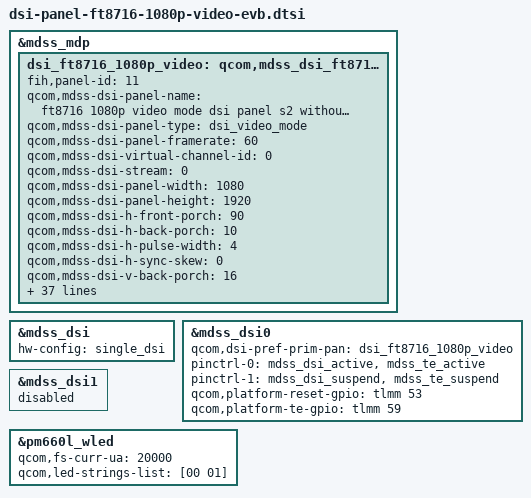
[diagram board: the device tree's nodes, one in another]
/* Copyright (c) 2015, The Linux Foundation. All rights reserved.
 *
 * This program is free software; you can redistribute it and/or modify
 * it under the terms of the GNU General Public License version 2 and
 * only version 2 as published by the Free Software Foundation.
 *
 * This program is distributed in the hope that it will be useful,
 * but WITHOUT ANY WARRANTY; without even the implied warranty of
 * MERCHANTABILITY or FITNESS FOR A PARTICULAR PURPOSE.  See the
 * GNU General Public License for more details.
 */

/*---------------------------------------------------------------------------
 * Templated from dsi-panel-r69006-1080p-video.dtsi
 *---------------------------------------------------------------------------*/
&mdss_mdp {
	dsi_ft8716_1080p_video: qcom,mdss_dsi_ft8716_1080p_video_s2 {
		fih,panel-id = <11>;
		qcom,mdss-dsi-panel-name = "ft8716 1080p video mode dsi panel s2 without DSC";
		qcom,mdss-dsi-panel-type = "dsi_video_mode";
		qcom,mdss-dsi-panel-framerate = <60>;
		qcom,mdss-dsi-virtual-channel-id = <0>;
		qcom,mdss-dsi-stream = <0>;
		qcom,mdss-dsi-panel-width = <1080>;
		qcom,mdss-dsi-panel-height = <1920>;
		qcom,mdss-dsi-h-front-porch = <90>;
		qcom,mdss-dsi-h-back-porch = <10>;
		qcom,mdss-dsi-h-pulse-width = <4>;
		qcom,mdss-dsi-h-sync-skew = <0>;
		qcom,mdss-dsi-v-back-porch = <16>;
		qcom,mdss-dsi-v-front-porch = <16>;
		qcom,mdss-dsi-v-pulse-width = <2>;
		qcom,mdss-dsi-h-left-border = <0>;
		qcom,mdss-dsi-h-right-border = <0>;
		qcom,mdss-dsi-v-top-border = <0>;
		qcom,mdss-dsi-v-bottom-border = <0>;
		qcom,mdss-dsi-bpp = <24>;
		qcom,mdss-dsi-underflow-color = <0xff>;
		qcom,mdss-dsi-border-color = <0>;
		qcom,mdss-dsi-on-command = [29 01 00 00 00 00 02 00 00
			29 01 00 00 00 00 04 ff 87 16 01
			29 01 00 00 00 00 02 00 80
			29 01 00 00 00 00 03 ff 87 16
			29 01 00 00 00 00 02 00 80
			29 01 00 00 00 00 0d d8 80 81 00 01 03 06 09 0b 0c 0b 0a 04
			29 01 00 00 00 00 02 00 90
			29 01 00 00 00 00 0d d8 00 01 01 01 01 00 00 00 01 01 02 05
			29 01 00 00 00 00 02 00 a0
			29 01 00 00 00 00 0d d8 01 02 06 09 0e 15 1b 22 26 26 26 22
			29 01 00 00 00 00 02 00 b0
			29 01 00 00 00 00 0d d8 81 84 86 88 8d 93 98 9d a1 a3 a3 a2
			29 01 00 00 00 00 02 00 c0
			29 01 00 00 00 00 0d d8 82 85 85 85 86 86 87 88 8a 8c 8e 94
			29 01 00 00 00 00 02 00 d0
			29 01 00 00 00 00 0d d8 02 05 07 0a 0d 10 13 17 1c 1d 1f 23
			29 01 00 00 00 00 02 00 e0
			29 01 00 00 00 00 04 d8 fd f0 f3
			29 01 00 00 00 00 02 00 c0
			29 01 00 00 00 00 02 d7 01
			29 01 00 00 00 00 02 00 b4
			29 01 00 00 00 00 02 c0 50
			29 01 00 00 00 00 02 00 00
			29 01 00 00 00 00 04 ff 00 00 00
			05 01 00 00 78 00 02 11 00
			05 01 00 00 0a 00 02 35 00
			05 01 00 00 00 00 02 29 00];
		qcom,mdss-dsi-off-command = [05 01 00 00 14 00 02 28 00
				 05 01 00 00 78 00 02 10 00];
		qcom,mdss-dsi-on-command-state = "dsi_lp_mode";
		qcom,mdss-dsi-off-command-state = "dsi_hs_mode";
		qcom,mdss-dsi-h-sync-pulse = <0>;
		qcom,mdss-dsi-traffic-mode = "non_burst_sync_event";
		qcom,mdss-dsi-bllp-eof-power-mode;
		qcom,mdss-dsi-bllp-power-mode;
		qcom,mdss-dsi-lane-0-state;
		qcom,mdss-dsi-lane-1-state;
		qcom,mdss-dsi-lane-2-state;
		qcom,mdss-dsi-lane-3-state;
		qcom,mdss-dsi-t-clk-post = <0x0d>;
		qcom,mdss-dsi-t-clk-pre = <0x2d>;
		qcom,mdss-dsi-dma-trigger = "trigger_sw";
		qcom,mdss-dsi-mdp-trigger = "none";
		qcom,mdss-dsi-reset-sequence = <1 1>, <0 1>, <1 15>;
	};
};

&dsi_ft8716_1080p_video {
	qcom,mdss-dsi-panel-timings-phy-v2 = [23 1e 07 09 05 03 04 a0
		23 1e 07 09 05 03 04 a0
		23 1e 07 09 05 03 04 a0
		23 1e 07 09 05 03 04 a0
		23 19 07 08 05 03 04 a0];
	qcom,mdss-dsi-bl-pmic-control-type = "bl_ctrl_wled";
	qcom,mdss-dsi-bl-min-level = <1>;
	qcom,mdss-dsi-bl-max-level = <4095>;
	qcom,panel-supply-entries = <&dsi_panel_pwr_supply>;
};

&mdss_dsi {
	hw-config = "single_dsi";
};

&mdss_dsi0 {
	qcom,dsi-pref-prim-pan = <&dsi_ft8716_1080p_video>;
	pinctrl-names = "mdss_default", "mdss_sleep";
	pinctrl-0 = <&mdss_dsi_active &mdss_te_active>;
	pinctrl-1 = <&mdss_dsi_suspend &mdss_te_suspend>;
	qcom,platform-reset-gpio = <&tlmm 53 0>;
	qcom,platform-te-gpio = <&tlmm 59 0>;
};

&mdss_dsi1 {
	status = "disabled";
};

&pm660l_wled {
	qcom,fs-curr-ua = <20000>;
	qcom,led-strings-list = [00 01];
};
